AUTOSAR XML (schema 4-2-2)
package /ComponentTypes
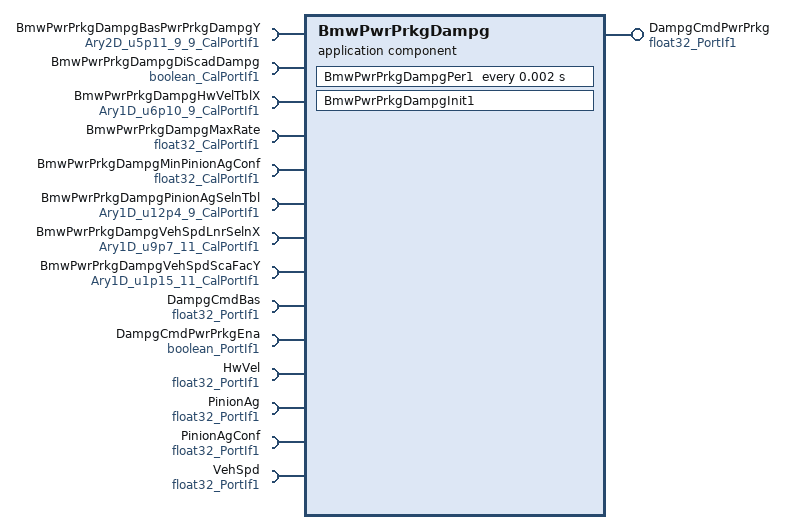
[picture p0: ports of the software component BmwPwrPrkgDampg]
  application sw component type BmwPwrPrkgDampg
    provide port DampgCmdPwrPrkg: nonqueued-sender-com-spec{data-element=Val, init-value=0}, provided-interface=float32_PortIf1
    14 x require port:
      BmwPwrPrkgDampgBasPwrPrkgDampgY: parameter-require-com-spec{init-value=[[0, 0, 0, 0, 205, 410, 614, 819, 1024], [0, 0, 0, 0, 205, 410, 614, 819, 1024], [0, 0, 0, 0, 205, 410, 614, 819, 1024], [0, 0, 0, 0, 205, 410, 614, 819, 1024], [0, 0, 0, 0, 205, 410, 614, 819, 1024], [0, 0, 0, 0, 205, 410, 614, 819, 1024], [0, 0, 0, 0, 205, 410, 614, 819, 1024], [0, 0, 0, 0, 154, 307, 471, 604, 819], [0, 0, 0, 0, 20, 41, 61, 82, 102]], parameter=Ary2D}, required-interface=Ary2D_u5p11_9_9_CalPortIf1
      BmwPwrPrkgDampgDiScadDampg: parameter-require-com-spec{init-value=1, parameter=Logl}, required-interface=boolean_CalPortIf1
      BmwPwrPrkgDampgHwVelTblX: parameter-require-com-spec{init-value=[0, 1280, 2560, 3840, 5120, 6400, 7680, 8960, 10240], parameter=Ary1D}, required-interface=Ary1D_u6p10_9_CalPortIf1
      BmwPwrPrkgDampgMaxRate: parameter-require-com-spec{init-value=1, parameter=Val}, required-interface=float32_CalPortIf1
      BmwPwrPrkgDampgMinPinionAgConf: parameter-require-com-spec{init-value=1, parameter=Val}, required-interface=float32_CalPortIf1
      BmwPwrPrkgDampgPinionAgSelnTbl: parameter-require-com-spec{init-value=[0, 1200, 2400, 3600, 4800, 6000, 7200, 8400, 9600], parameter=Ary1D}, required-interface=Ary1D_u12p4_9_CalPortIf1
      BmwPwrPrkgDampgVehSpdLnrSelnX: parameter-require-com-spec{init-value=[0, 256, 512, 768, 1024, 1280, 1536, 1792, 2048, 2304, 2560], parameter=Ary1D}, required-interface=Ary1D_u9p7_11_CalPortIf1
      BmwPwrPrkgDampgVehSpdScaFacY: parameter-require-com-spec{init-value=[32768, 32768, 32768, 32768, 32768, 32768, 26214, 19661, 13107, 6554, 0], parameter=Ary1D}, required-interface=Ary1D_u1p15_11_CalPortIf1
      DampgCmdBas: nonqueued-receiver-com-spec{data-element=Val, filter=data-filter-type=ALWAYS, init-value=0}, required-interface=float32_PortIf1
      DampgCmdPwrPrkgEna: nonqueued-receiver-com-spec{data-element=Logl, filter=data-filter-type=ALWAYS, init-value=0}, required-interface=boolean_PortIf1
      HwVel: nonqueued-receiver-com-spec{data-element=Val, filter=data-filter-type=ALWAYS, init-value=0}, required-interface=float32_PortIf1
      PinionAg: nonqueued-receiver-com-spec{data-element=Val, filter=data-filter-type=ALWAYS, init-value=0}, required-interface=float32_PortIf1
      PinionAgConf: nonqueued-receiver-com-spec{data-element=Val, filter=data-filter-type=ALWAYS, init-value=0}, required-interface=float32_PortIf1
      VehSpd: nonqueued-receiver-com-spec{data-element=Val, filter=data-filter-type=ALWAYS, init-value=0}, required-interface=float32_PortIf1
    behavior BmwPwrPrkgDampg_InternalBehavior
      ar-typed-per-instance-memorys:
        data DampgCmdPwrPrkgStVari: sw-calibration-access=READ-ONLY, type=float32
      init event BmwPwrPrkgDampg_InitEvent: start-on-event=BmwPwrPrkgDampgInit1
      timing event TMT_BmwPwrPrkgDampgPer1: start-on-event=BmwPwrPrkgDampgPer1, period=0.002
      port-api-options:
        enable-take-address=false, error-handling=NO-TRANSFORMER-ERROR-HANDLING, indirect-api=false, port=BmwPwrPrkgDampgBasPwrPrkgDampgY
        enable-take-address=false, error-handling=NO-TRANSFORMER-ERROR-HANDLING, indirect-api=false, port=BmwPwrPrkgDampgDiScadDampg
        enable-take-address=false, error-handling=NO-TRANSFORMER-ERROR-HANDLING, indirect-api=false, port=BmwPwrPrkgDampgHwVelTblX
        enable-take-address=false, error-handling=NO-TRANSFORMER-ERROR-HANDLING, indirect-api=false, port=BmwPwrPrkgDampgMaxRate
        enable-take-address=false, error-handling=NO-TRANSFORMER-ERROR-HANDLING, indirect-api=false, port=BmwPwrPrkgDampgMinPinionAgConf
        enable-take-address=false, error-handling=NO-TRANSFORMER-ERROR-HANDLING, indirect-api=false, port=BmwPwrPrkgDampgPinionAgSelnTbl
        enable-take-address=false, error-handling=NO-TRANSFORMER-ERROR-HANDLING, indirect-api=false, port=BmwPwrPrkgDampgVehSpdLnrSelnX
        enable-take-address=false, error-handling=NO-TRANSFORMER-ERROR-HANDLING, indirect-api=false, port=BmwPwrPrkgDampgVehSpdScaFacY
        enable-take-address=false, error-handling=NO-TRANSFORMER-ERROR-HANDLING, indirect-api=false, port=DampgCmdBas
        enable-take-address=false, error-handling=NO-TRANSFORMER-ERROR-HANDLING, indirect-api=false, port=DampgCmdPwrPrkg
        enable-take-address=false, error-handling=NO-TRANSFORMER-ERROR-HANDLING, indirect-api=false, port=DampgCmdPwrPrkgEna
        enable-take-address=false, error-handling=NO-TRANSFORMER-ERROR-HANDLING, indirect-api=false, port=HwVel
        enable-take-address=false, error-handling=NO-TRANSFORMER-ERROR-HANDLING, indirect-api=false, port=PinionAg
        enable-take-address=false, error-handling=NO-TRANSFORMER-ERROR-HANDLING, indirect-api=false, port=PinionAgConf
        enable-take-address=false, error-handling=NO-TRANSFORMER-ERROR-HANDLING, indirect-api=false, port=VehSpd
      runnable BmwPwrPrkgDampgInit1
      runnable BmwPwrPrkgDampgPer1
        data-receive-point-by-arguments:
          6 x access:
            REC_DampgCmdBas_Val: accessed-variable=DampgCmdBas.Val
            REC_DampgCmdPwrPrkgEna_Logl: accessed-variable=DampgCmdPwrPrkgEna.Logl
            REC_HwVel_Val: accessed-variable=HwVel.Val
            REC_PinionAg_Val: accessed-variable=PinionAg.Val
            REC_PinionAgConf_Val: accessed-variable=PinionAgConf.Val
            REC_VehSpd_Val: accessed-variable=VehSpd.Val
        data-send-points:
          access SEND_DampgCmdPwrPrkg_Val: accessed-variable=DampgCmdPwrPrkg.Val
  swc implementation BmwPwrPrkgDampg_Implementation: behavior=BmwPwrPrkgDampg_InternalBehavior
    code-descriptors:
      code Default: artifact-descriptors=autosar-engineering-object={short-label=Default, category=SWSRC}
